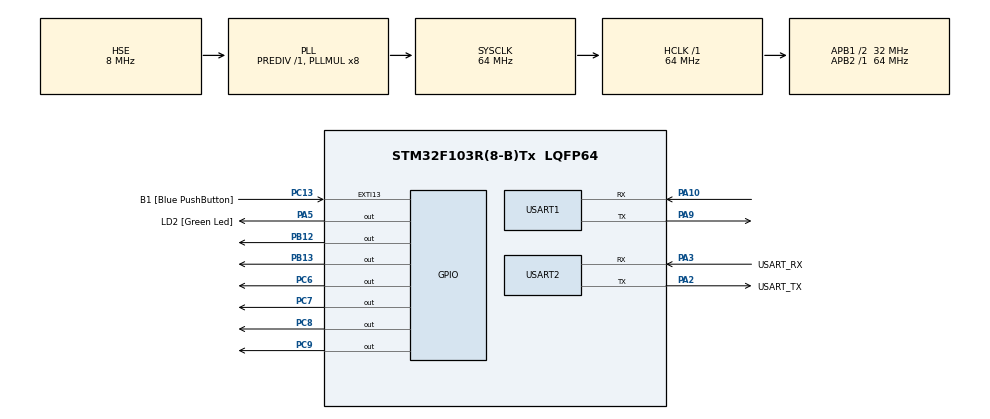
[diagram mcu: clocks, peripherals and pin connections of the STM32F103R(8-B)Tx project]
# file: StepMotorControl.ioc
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Mcu.Family=STM32F1
Mcu.Name=STM32F103R(8-B)Tx
Mcu.Package=LQFP64
NVIC.EXTI15_10_IRQn=true\:0\:0\:false\:false\:true\:true\:true\:true
NVIC.PriorityGroup=NVIC_PRIORITYGROUP_4
NVIC.USART1_IRQn=true\:0\:0\:false\:false\:true\:true\:true\:true
PA10.Mode=Asynchronous
PA10.Signal=USART1_RX
PA13.GPIO_Label=TMS
PA13.Mode=Serial_Wire
PA13.Signal=SYS_JTMS-SWDIO
PA14.GPIO_Label=TCK
PA14.Mode=Serial_Wire
PA14.Signal=SYS_JTCK-SWCLK
PA2.GPIO_Label=USART_TX
PA2.GPIO_Mode=GPIO_MODE_AF_PP
PA2.GPIO_PuPd=GPIO_NOPULL
PA2.GPIO_Speed=GPIO_SPEED_FREQ_LOW
PA2.Mode=Asynchronous
PA2.Signal=USART2_TX
PA3.GPIO_Label=USART_RX
PA3.GPIO_Mode=GPIO_MODE_AF_PP
PA3.GPIO_PuPd=GPIO_NOPULL
PA3.GPIO_Speed=GPIO_SPEED_FREQ_LOW
PA3.Mode=Asynchronous
PA3.Signal=USART2_RX
PA5.GPIO_Label=LD2 [Green Led]
PA5.GPIO_ModeDefaultOutputPP=GPIO_MODE_OUTPUT_PP
PA5.GPIO_PuPd=GPIO_NOPULL
PA5.GPIO_Speed=GPIO_SPEED_FREQ_LOW
PA5.Signal=GPIO_Output
PA9.Mode=Asynchronous
PA9.Signal=USART1_TX
PB10.Signal=USART3_TX
PB11.Signal=USART3_RX
PB12.Signal=GPIO_Output
PB13.Signal=GPIO_Output
PB3.GPIO_Label=SWO
PB3.Signal=SYS_JTDO-TRACESWO
PC13-TAMPER-RTC.GPIO_Label=B1 [Blue PushButton]
PC13-TAMPER-RTC.GPIO_PuPd=GPIO_NOPULL
PC13-TAMPER-RTC.Signal=GPXTI13
PC14-OSC32_IN.Mode=LSE-External-Oscillator
PC14-OSC32_IN.Signal=RCC_OSC32_IN
PC15-OSC32_OUT.Mode=LSE-External-Oscillator
PC15-OSC32_OUT.Signal=RCC_OSC32_OUT
PC6.GPIO_PuPd=GPIO_PULLUP
PC6.PinState=GPIO_PIN_SET
PC6.Signal=GPIO_Output
PC7.GPIO_PuPd=GPIO_PULLUP
PC7.PinState=GPIO_PIN_SET
PC7.Signal=GPIO_Output
PC8.GPIO_PuPd=GPIO_PULLUP
PC8.PinState=GPIO_PIN_SET
PC8.Signal=GPIO_Output
PC9.GPIO_PuPd=GPIO_PULLUP
PC9.PinState=GPIO_PIN_SET
PC9.Signal=GPIO_Output
PD0-OSC_IN.Mode=HSE-External-Clock-Source
PD0-OSC_IN.Signal=RCC_OSC_IN
PD1-OSC_OUT.Mode=HSE-External-Clock-Source
PD1-OSC_OUT.Signal=RCC_OSC_OUT
ProjectManager.HeapSize=0x200
ProjectManager.StackSize=0x400
ProjectManager.TargetToolchain=STM32CubeIDE
RCC.AHBFreq_Value=64000000
RCC.APB1CLKDivider=RCC_HCLK_DIV2
RCC.APB1Freq_Value=32000000
RCC.APB1TimFreq_Value=64000000
RCC.APB2Freq_Value=64000000
RCC.APB2TimFreq_Value=64000000
RCC.HCLKFreq_Value=64000000
RCC.PLLMUL=RCC_PLL_MUL8
RCC.PLLSourceVirtual=RCC_PLLSOURCE_HSE
RCC.RTCClockSelection=RCC_RTCCLKSOURCE_LSE
RCC.SYSCLKFreq_VALUE=64000000
RCC.SYSCLKSource=RCC_SYSCLKSOURCE_PLLCLK
RCC.USBFreq_Value=64000000
USART1.VirtualMode=VM_ASYNC
USART2.VirtualMode=VM_ASYNC
board=NUCLEO-F103RB

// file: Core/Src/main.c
/* USER CODE BEGIN Header */
/**
  ******************************************************************************
  * @file           : main.c
  * @brief          : Main program body
  ******************************************************************************
  * @attention
  *
  * Copyright (c) 2023 STMicroelectronics.
  * All rights reserved.
  *
  * This software is licensed under terms that can be found in the LICENSE file
  * in the root directory of this software component.
  * If no LICENSE file comes with this software, it is provided AS-IS.
  *
  ******************************************************************************
  */
#include "../Inc/stepMotor/stepMotor.h"
#include "../Inc/uart/uart.h"
#include "sys/_stdint.h"
#include "../Inc/sys/systick.h"

/* USER CODE END Header */
#include "main.h"

UART_HandleTypeDef huart2;

/* USER CODE BEGIN PV */
uint8_t uart3Buf;
extern uint16_t vStepAngle;
extern uint8_t vStep_StartFlag;
/* USER CODE END PV */

void SystemClock_Config(void);
static void MX_GPIO_Init(void);
static void MX_USART2_UART_Init(void);
static void MX_USART1_UART_Init(void);

/* USER CODE BEGIN 0 */
uint8_t __io_putchar(uint8_t ch)
{
	UART1_Write(ch);
	return ch;
}
/* USER CODE END 0 */

int main(void)
{

  /* MCU Configuration--------------------------------------------------------*/

  /* Reset of all peripherals, Initializes the Flash interface and the Systick. */
  HAL_Init();

  /* Configure the system clock */
  SystemClock_Config();

  /* Initialize all configured peripherals */
  MX_GPIO_Init();
  MX_USART2_UART_Init();
  MX_USART1_UART_Init();
  /* USER CODE BEGIN 2 */
  //Enable L298N Motor Driver
  LL_GPIO_SetOutputPin(GPIOB, LL_GPIO_PIN_12);
  LL_GPIO_SetOutputPin(GPIOB, LL_GPIO_PIN_13);

//  USART1_RX_IT_Set(1);
  UART_Enable_RX_IT();

  SysTimerSetting();

  StepMotor_Init();
  /* USER CODE END 2 */

  /* Infinite loop */
  /* USER CODE BEGIN WHILE */
  while (1)
  {
	//10ms Task
	  //
	  if(vStep_StartFlag == 1)
	  {
		StepMotor_SetMotorAngle(vStepAngle, 10);
		vStep_StartFlag = 0;
	  }

    /* USER CODE END WHILE */

  }
}

void SystemClock_Config(void)
{
  RCC_OscInitTypeDef RCC_OscInitStruct = {0};
  RCC_ClkInitTypeDef RCC_ClkInitStruct = {0};

  /** Initializes the RCC Oscillators according to the specified parameters
  * in the RCC_OscInitTypeDef structure.
  */
  RCC_OscInitStruct.OscillatorType = RCC_OSCILLATORTYPE_HSE;
  RCC_OscInitStruct.HSEState = RCC_HSE_BYPASS;
  RCC_OscInitStruct.HSEPredivValue = RCC_HSE_PREDIV_DIV1;
  RCC_OscInitStruct.HSIState = RCC_HSI_ON;
  RCC_OscInitStruct.PLL.PLLState = RCC_PLL_ON;
  RCC_OscInitStruct.PLL.PLLSource = RCC_PLLSOURCE_HSE;
  RCC_OscInitStruct.PLL.PLLMUL = RCC_PLL_MUL8;
  if (HAL_RCC_OscConfig(&RCC_OscInitStruct) != HAL_OK)
  {
    Error_Handler();
  }

  /** Initializes the CPU, AHB and APB buses clocks
  */
  RCC_ClkInitStruct.ClockType = RCC_CLOCKTYPE_HCLK|RCC_CLOCKTYPE_SYSCLK
                              |RCC_CLOCKTYPE_PCLK1|RCC_CLOCKTYPE_PCLK2;
  RCC_ClkInitStruct.SYSCLKSource = RCC_SYSCLKSOURCE_PLLCLK;
  RCC_ClkInitStruct.AHBCLKDivider = RCC_SYSCLK_DIV1;
  RCC_ClkInitStruct.APB1CLKDivider = RCC_HCLK_DIV2;
  RCC_ClkInitStruct.APB2CLKDivider = RCC_HCLK_DIV1;

  if (HAL_RCC_ClockConfig(&RCC_ClkInitStruct, FLASH_LATENCY_2) != HAL_OK)
  {
    Error_Handler();
  }
}

static void MX_USART1_UART_Init(void)
{

  LL_USART_InitTypeDef USART_InitStruct = {0};

  LL_GPIO_InitTypeDef GPIO_InitStruct = {0};

  /* Peripheral clock enable */
  LL_APB2_GRP1_EnableClock(LL_APB2_GRP1_PERIPH_USART1);

  LL_APB2_GRP1_EnableClock(LL_APB2_GRP1_PERIPH_GPIOA);
  /**USART1 GPIO Configuration
  PA9   ------> USART1_TX
  PA10   ------> USART1_RX
  */
  GPIO_InitStruct.Pin = LL_GPIO_PIN_9;
  GPIO_InitStruct.Mode = LL_GPIO_MODE_ALTERNATE;
  GPIO_InitStruct.Speed = LL_GPIO_SPEED_FREQ_HIGH;
  GPIO_InitStruct.OutputType = LL_GPIO_OUTPUT_PUSHPULL;
  LL_GPIO_Init(GPIOA, &GPIO_InitStruct);

  GPIO_InitStruct.Pin = LL_GPIO_PIN_10;
  GPIO_InitStruct.Mode = LL_GPIO_MODE_FLOATING;
  LL_GPIO_Init(GPIOA, &GPIO_InitStruct);

  /* USART1 interrupt Init */
  NVIC_SetPriority(USART1_IRQn, NVIC_EncodePriority(NVIC_GetPriorityGrouping(),0, 0));
  NVIC_EnableIRQ(USART1_IRQn);

  USART_InitStruct.BaudRate = 115200;
  USART_InitStruct.DataWidth = LL_USART_DATAWIDTH_8B;
  USART_InitStruct.StopBits = LL_USART_STOPBITS_1;
  USART_InitStruct.Parity = LL_USART_PARITY_NONE;
  USART_InitStruct.TransferDirection = LL_USART_DIRECTION_TX_RX;
  USART_InitStruct.HardwareFlowControl = LL_USART_HWCONTROL_NONE;
  USART_InitStruct.OverSampling = LL_USART_OVERSAMPLING_16;
  LL_USART_Init(USART1, &USART_InitStruct);
  LL_USART_ConfigAsyncMode(USART1);
  LL_USART_Enable(USART1);

}

static void MX_USART2_UART_Init(void)
{

  huart2.Instance = USART2;
  huart2.Init.BaudRate = 115200;
  huart2.Init.WordLength = UART_WORDLENGTH_8B;
  huart2.Init.StopBits = UART_STOPBITS_1;
  huart2.Init.Parity = UART_PARITY_NONE;
  huart2.Init.Mode = UART_MODE_TX_RX;
  huart2.Init.HwFlowCtl = UART_HWCONTROL_NONE;
  huart2.Init.OverSampling = UART_OVERSAMPLING_16;
  if (HAL_UART_Init(&huart2) != HAL_OK)
  {
    Error_Handler();
  }

}

static void MX_GPIO_Init(void)
{
  LL_EXTI_InitTypeDef EXTI_InitStruct = {0};
  LL_GPIO_InitTypeDef GPIO_InitStruct = {0};

  /* GPIO Ports Clock Enable */
  LL_APB2_GRP1_EnableClock(LL_APB2_GRP1_PERIPH_GPIOC);
  LL_APB2_GRP1_EnableClock(LL_APB2_GRP1_PERIPH_GPIOD);
  LL_APB2_GRP1_EnableClock(LL_APB2_GRP1_PERIPH_GPIOA);
  LL_APB2_GRP1_EnableClock(LL_APB2_GRP1_PERIPH_GPIOB);

  /**/
  LL_GPIO_ResetOutputPin(LD2_GPIO_Port, LD2_Pin);

  /**/
  LL_GPIO_ResetOutputPin(GPIOB, LL_GPIO_PIN_12|LL_GPIO_PIN_13);

  /**/
  LL_GPIO_SetOutputPin(GPIOC, LL_GPIO_PIN_6|LL_GPIO_PIN_7|LL_GPIO_PIN_8|LL_GPIO_PIN_9);

  /**/
  LL_GPIO_AF_SetEXTISource(LL_GPIO_AF_EXTI_PORTC, LL_GPIO_AF_EXTI_LINE13);

  /**/
  EXTI_InitStruct.Line_0_31 = LL_EXTI_LINE_13;
  EXTI_InitStruct.LineCommand = ENABLE;
  EXTI_InitStruct.Mode = LL_EXTI_MODE_IT;
  EXTI_InitStruct.Trigger = LL_EXTI_TRIGGER_RISING;
  LL_EXTI_Init(&EXTI_InitStruct);

  /**/
  LL_GPIO_SetPinMode(B1_GPIO_Port, B1_Pin, LL_GPIO_MODE_FLOATING);

  /**/
  GPIO_InitStruct.Pin = LD2_Pin;
  GPIO_InitStruct.Mode = LL_GPIO_MODE_OUTPUT;
  GPIO_InitStruct.Speed = LL_GPIO_SPEED_FREQ_LOW;
  GPIO_InitStruct.OutputType = LL_GPIO_OUTPUT_PUSHPULL;
  LL_GPIO_Init(LD2_GPIO_Port, &GPIO_InitStruct);

  /**/
  GPIO_InitStruct.Pin = LL_GPIO_PIN_10;
  GPIO_InitStruct.Mode = LL_GPIO_MODE_ALTERNATE;
  GPIO_InitStruct.Speed = LL_GPIO_SPEED_FREQ_HIGH;
  GPIO_InitStruct.OutputType = LL_GPIO_OUTPUT_PUSHPULL;
  LL_GPIO_Init(GPIOB, &GPIO_InitStruct);

  /**/
  GPIO_InitStruct.Pin = LL_GPIO_PIN_11;
  GPIO_InitStruct.Mode = LL_GPIO_MODE_FLOATING;
  LL_GPIO_Init(GPIOB, &GPIO_InitStruct);

  /**/
  GPIO_InitStruct.Pin = LL_GPIO_PIN_12|LL_GPIO_PIN_13;
  GPIO_InitStruct.Mode = LL_GPIO_MODE_OUTPUT;
  GPIO_InitStruct.Speed = LL_GPIO_SPEED_FREQ_LOW;
  GPIO_InitStruct.OutputType = LL_GPIO_OUTPUT_PUSHPULL;
  LL_GPIO_Init(GPIOB, &GPIO_InitStruct);

  /**/
  GPIO_InitStruct.Pin = LL_GPIO_PIN_6|LL_GPIO_PIN_7|LL_GPIO_PIN_8|LL_GPIO_PIN_9;
  GPIO_InitStruct.Mode = LL_GPIO_MODE_OUTPUT;
  GPIO_InitStruct.Speed = LL_GPIO_SPEED_FREQ_LOW;
  GPIO_InitStruct.OutputType = LL_GPIO_OUTPUT_PUSHPULL;
  GPIO_InitStruct.Pull = LL_GPIO_PULL_UP;
  LL_GPIO_Init(GPIOC, &GPIO_InitStruct);

  /* EXTI interrupt init*/
  NVIC_SetPriority(EXTI15_10_IRQn, NVIC_EncodePriority(NVIC_GetPriorityGrouping(),0, 0));
  NVIC_EnableIRQ(EXTI15_10_IRQn);

}

void Error_Handler(void)
{
  __disable_irq();
  while (1)
  {
  }
}
